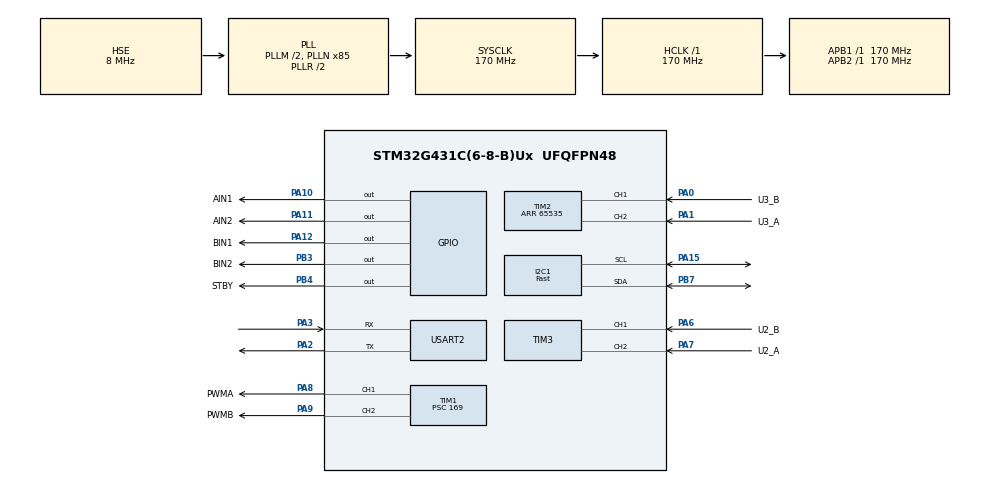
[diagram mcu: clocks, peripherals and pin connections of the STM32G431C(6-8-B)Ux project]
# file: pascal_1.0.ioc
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I2C1.I2C_Speed_Mode=I2C_Fast
I2C1.Timing=0x40621236
Mcu.Family=STM32G4
Mcu.Name=STM32G431C(6-8-B)Ux
Mcu.Package=UFQFPN48
NVIC.I2C1_EV_IRQn=true\:0\:0\:false\:false\:true\:true\:true\:true
NVIC.PriorityGroup=NVIC_PRIORITYGROUP_4
NVIC.TIM2_IRQn=true\:0\:0\:false\:false\:true\:true\:true\:true
NVIC.TIM3_IRQn=true\:0\:0\:false\:false\:true\:true\:true\:true
PA0.GPIO_Label=U3_B
PA0.GPIO_PuPd=GPIO_PULLDOWN
PA0.Signal=S_TIM2_CH1
PA1.GPIO_Label=U3_A
PA1.GPIO_PuPd=GPIO_PULLDOWN
PA1.Signal=S_TIM2_CH2
PA10.GPIO_Label=AIN1
PA10.Signal=GPIO_Output
PA11.GPIO_Label=AIN2
PA11.Signal=GPIO_Output
PA12.GPIO_Label=BIN1
PA12.Signal=GPIO_Output
PA13.Mode=Serial_Wire
PA13.Signal=SYS_JTMS-SWDIO
PA14.Mode=Serial_Wire
PA14.Signal=SYS_JTCK-SWCLK
PA15.Mode=I2C
PA15.Signal=I2C1_SCL
PA2.Mode=Asynchronous
PA2.Signal=USART2_TX
PA3.Mode=Asynchronous
PA3.Signal=USART2_RX
PA6.GPIO_Label=U2_B
PA6.GPIO_PuPd=GPIO_PULLDOWN
PA6.Signal=S_TIM3_CH1
PA7.GPIO_Label=U2_A
PA7.GPIO_PuPd=GPIO_PULLDOWN
PA7.Signal=S_TIM3_CH2
PA8.GPIO_Label=PWMA
PA8.Signal=S_TIM1_CH1
PA9.GPIO_Label=PWMB
PA9.Signal=S_TIM1_CH2
PB3.GPIO_Label=BIN2
PB3.Signal=GPIO_Output
PB4.GPIO_Label=STBY
PB4.Signal=GPIO_Output
PB7.Mode=I2C
PB7.Signal=I2C1_SDA
PF0-OSC_IN.Mode=HSE-External-Oscillator
PF0-OSC_IN.Signal=RCC_OSC_IN
PF1-OSC_OUT.Mode=HSE-External-Oscillator
PF1-OSC_OUT.Signal=RCC_OSC_OUT
ProjectManager.HeapSize=0x200
ProjectManager.StackSize=0x400
ProjectManager.TargetToolchain=STM32CubeIDE
RCC.ADC12Freq_Value=170000000
RCC.AHBFreq_Value=170000000
RCC.APB1Freq_Value=170000000
RCC.APB1TimFreq_Value=170000000
RCC.APB2Freq_Value=170000000
RCC.APB2TimFreq_Value=170000000
RCC.CortexFreq_Value=170000000
RCC.EXTERNAL_CLOCK_VALUE=12288000
RCC.HCLKFreq_Value=170000000
RCC.HSE_VALUE=8000000
RCC.HSI48_VALUE=48000000
RCC.HSI_VALUE=16000000
RCC.LSE_VALUE=32768
RCC.PLLM=RCC_PLLM_DIV2
RCC.PLLN=85
RCC.PLLSourceVirtual=RCC_PLLSOURCE_HSE
RCC.SYSCLKFreq_VALUE=170000000
RCC.SYSCLKSource=RCC_SYSCLKSOURCE_PLLCLK
RCC.USBFreq_Value=170000000
RCC.VCOOutputFreq_Value=340000000
SH.S_TIM1_CH1.0=TIM1_CH1,PWM Generation1 CH1
SH.S_TIM1_CH2.0=TIM1_CH2,PWM Generation2 CH2
SH.S_TIM2_CH1.0=TIM2_CH1,Encoder_Interface
SH.S_TIM2_CH2.0=TIM2_CH2,Encoder_Interface
SH.S_TIM3_CH1.0=TIM3_CH1,Encoder_Interface
SH.S_TIM3_CH2.0=TIM3_CH2,Encoder_Interface
TIM1.Channel-PWM\ Generation1\ CH1=TIM_CHANNEL_1
TIM1.Channel-PWM\ Generation2\ CH2=TIM_CHANNEL_2
TIM1.PeriodNoDither=1000
TIM1.Prescaler=169
TIM2.PeriodNoDither=65535
USART2.VirtualMode-Asynchronous=VM_ASYNC
VP_SYS_VS_DBSignals.Mode=DisableDeadBatterySignals
board=custom

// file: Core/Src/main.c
/* USER CODE BEGIN Header */
/**
  ******************************************************************************
  * @file           : main.c
  * @brief          : Main program body
  ******************************************************************************
  * @attention
  *
  * Copyright (c) 2026 STMicroelectronics.
  * All rights reserved.
  *
  * This software is licensed under terms that can be found in the LICENSE file
  * in the root directory of this software component.
  * If no LICENSE file comes with this software, it is provided AS-IS.
  *
  ******************************************************************************
  */
/* USER CODE END Header */
#include "main.h"

/* USER CODE BEGIN Includes */
#include "motor.h"
#include "encoder.h"
#include <stdio.h>
/* USER CODE END Includes */

I2C_HandleTypeDef hi2c1;

TIM_HandleTypeDef htim1;
TIM_HandleTypeDef htim2;
TIM_HandleTypeDef htim3;

UART_HandleTypeDef huart2;

/* USER CODE BEGIN PV */

//float d = 0;
int16_t speed=950;

/* USER CODE END PV */

void SystemClock_Config(void);
static void MX_GPIO_Init(void);
static void MX_I2C1_Init(void);
static void MX_TIM1_Init(void);
static void MX_TIM2_Init(void);
static void MX_TIM3_Init(void);
static void MX_USART2_UART_Init(void);

/* USER CODE BEGIN 0 */
int __io_putchar(int ch)
{
    HAL_UART_Transmit(&huart2, (uint8_t*)&ch, 1, HAL_MAX_DELAY);
    return ch;
}
/* USER CODE END 0 */

int main(void)
{

  /* MCU Configuration--------------------------------------------------------*/

  /* Reset of all peripherals, Initializes the Flash interface and the Systick. */
  HAL_Init();

  /* Configure the system clock */
  SystemClock_Config();

  /* Initialize all configured peripherals */
  MX_GPIO_Init();
  MX_I2C1_Init();
  MX_TIM1_Init();
  MX_TIM2_Init();
  MX_TIM3_Init();
  MX_USART2_UART_Init();
  /* USER CODE BEGIN 2 */
  Motor_Init();
  Encoder_Init();
  /* USER CODE END 2 */

  /* Infinite loop */
  while (1)
  {

    /* USER CODE BEGIN 3 */

//	  Motor_Forward(speed);

	  Encoder_Update();
//
	  printf("%f %f \r\n",Encoder_GetDistanceLeft(),Encoder_GetDistanceRight());
//
	  HAL_Delay(50);

	  //HAL_Delay(200);
  }
  /* USER CODE END 3 */
}

void SystemClock_Config(void)
{
  RCC_OscInitTypeDef RCC_OscInitStruct = {0};
  RCC_ClkInitTypeDef RCC_ClkInitStruct = {0};

  /** Configure the main internal regulator output voltage
  */
  HAL_PWREx_ControlVoltageScaling(PWR_REGULATOR_VOLTAGE_SCALE1_BOOST);

  /** Initializes the RCC Oscillators according to the specified parameters
  * in the RCC_OscInitTypeDef structure.
  */
  RCC_OscInitStruct.OscillatorType = RCC_OSCILLATORTYPE_HSE;
  RCC_OscInitStruct.HSEState = RCC_HSE_ON;
  RCC_OscInitStruct.PLL.PLLState = RCC_PLL_ON;
  RCC_OscInitStruct.PLL.PLLSource = RCC_PLLSOURCE_HSE;
  RCC_OscInitStruct.PLL.PLLM = RCC_PLLM_DIV2;
  RCC_OscInitStruct.PLL.PLLN = 85;
  RCC_OscInitStruct.PLL.PLLP = RCC_PLLP_DIV2;
  RCC_OscInitStruct.PLL.PLLQ = RCC_PLLQ_DIV2;
  RCC_OscInitStruct.PLL.PLLR = RCC_PLLR_DIV2;
  if (HAL_RCC_OscConfig(&RCC_OscInitStruct) != HAL_OK)
  {
    Error_Handler();
  }

  /** Initializes the CPU, AHB and APB buses clocks
  */
  RCC_ClkInitStruct.ClockType = RCC_CLOCKTYPE_HCLK|RCC_CLOCKTYPE_SYSCLK
                              |RCC_CLOCKTYPE_PCLK1|RCC_CLOCKTYPE_PCLK2;
  RCC_ClkInitStruct.SYSCLKSource = RCC_SYSCLKSOURCE_PLLCLK;
  RCC_ClkInitStruct.AHBCLKDivider = RCC_SYSCLK_DIV1;
  RCC_ClkInitStruct.APB1CLKDivider = RCC_HCLK_DIV1;
  RCC_ClkInitStruct.APB2CLKDivider = RCC_HCLK_DIV1;

  if (HAL_RCC_ClockConfig(&RCC_ClkInitStruct, FLASH_LATENCY_4) != HAL_OK)
  {
    Error_Handler();
  }
}

static void MX_I2C1_Init(void)
{

  hi2c1.Instance = I2C1;
  hi2c1.Init.Timing = 0x40621236;
  hi2c1.Init.OwnAddress1 = 0;
  hi2c1.Init.AddressingMode = I2C_ADDRESSINGMODE_7BIT;
  hi2c1.Init.DualAddressMode = I2C_DUALADDRESS_DISABLE;
  hi2c1.Init.OwnAddress2 = 0;
  hi2c1.Init.OwnAddress2Masks = I2C_OA2_NOMASK;
  hi2c1.Init.GeneralCallMode = I2C_GENERALCALL_DISABLE;
  hi2c1.Init.NoStretchMode = I2C_NOSTRETCH_DISABLE;
  if (HAL_I2C_Init(&hi2c1) != HAL_OK)
  {
    Error_Handler();
  }

  /** Configure Analogue filter
  */
  if (HAL_I2CEx_ConfigAnalogFilter(&hi2c1, I2C_ANALOGFILTER_ENABLE) != HAL_OK)
  {
    Error_Handler();
  }

  /** Configure Digital filter
  */
  if (HAL_I2CEx_ConfigDigitalFilter(&hi2c1, 0) != HAL_OK)
  {
    Error_Handler();
  }

}

static void MX_TIM1_Init(void)
{

  TIM_MasterConfigTypeDef sMasterConfig = {0};
  TIM_OC_InitTypeDef sConfigOC = {0};
  TIM_BreakDeadTimeConfigTypeDef sBreakDeadTimeConfig = {0};

  htim1.Instance = TIM1;
  htim1.Init.Prescaler = 169;
  htim1.Init.CounterMode = TIM_COUNTERMODE_UP;
  htim1.Init.Period = 1000;
  htim1.Init.ClockDivision = TIM_CLOCKDIVISION_DIV1;
  htim1.Init.RepetitionCounter = 0;
  htim1.Init.AutoReloadPreload = TIM_AUTORELOAD_PRELOAD_DISABLE;
  if (HAL_TIM_PWM_Init(&htim1) != HAL_OK)
  {
    Error_Handler();
  }
  sMasterConfig.MasterOutputTrigger = TIM_TRGO_RESET;
  sMasterConfig.MasterOutputTrigger2 = TIM_TRGO2_RESET;
  sMasterConfig.MasterSlaveMode = TIM_MASTERSLAVEMODE_DISABLE;
  if (HAL_TIMEx_MasterConfigSynchronization(&htim1, &sMasterConfig) != HAL_OK)
  {
    Error_Handler();
  }
  sConfigOC.OCMode = TIM_OCMODE_PWM1;
  sConfigOC.Pulse = 0;
  sConfigOC.OCPolarity = TIM_OCPOLARITY_HIGH;
  sConfigOC.OCNPolarity = TIM_OCNPOLARITY_HIGH;
  sConfigOC.OCFastMode = TIM_OCFAST_DISABLE;
  sConfigOC.OCIdleState = TIM_OCIDLESTATE_RESET;
  sConfigOC.OCNIdleState = TIM_OCNIDLESTATE_RESET;
  if (HAL_TIM_PWM_ConfigChannel(&htim1, &sConfigOC, TIM_CHANNEL_1) != HAL_OK)
  {
    Error_Handler();
  }
  if (HAL_TIM_PWM_ConfigChannel(&htim1, &sConfigOC, TIM_CHANNEL_2) != HAL_OK)
  {
    Error_Handler();
  }
  sBreakDeadTimeConfig.OffStateRunMode = TIM_OSSR_DISABLE;
  sBreakDeadTimeConfig.OffStateIDLEMode = TIM_OSSI_DISABLE;
  sBreakDeadTimeConfig.LockLevel = TIM_LOCKLEVEL_OFF;
  sBreakDeadTimeConfig.DeadTime = 0;
  sBreakDeadTimeConfig.BreakState = TIM_BREAK_DISABLE;
  sBreakDeadTimeConfig.BreakPolarity = TIM_BREAKPOLARITY_HIGH;
  sBreakDeadTimeConfig.BreakFilter = 0;
  sBreakDeadTimeConfig.BreakAFMode = TIM_BREAK_AFMODE_INPUT;
  sBreakDeadTimeConfig.Break2State = TIM_BREAK2_DISABLE;
  sBreakDeadTimeConfig.Break2Polarity = TIM_BREAK2POLARITY_HIGH;
  sBreakDeadTimeConfig.Break2Filter = 0;
  sBreakDeadTimeConfig.Break2AFMode = TIM_BREAK_AFMODE_INPUT;
  sBreakDeadTimeConfig.AutomaticOutput = TIM_AUTOMATICOUTPUT_DISABLE;
  if (HAL_TIMEx_ConfigBreakDeadTime(&htim1, &sBreakDeadTimeConfig) != HAL_OK)
  {
    Error_Handler();
  }
  HAL_TIM_MspPostInit(&htim1);

}

static void MX_TIM2_Init(void)
{

  TIM_Encoder_InitTypeDef sConfig = {0};
  TIM_MasterConfigTypeDef sMasterConfig = {0};

  htim2.Instance = TIM2;
  htim2.Init.Prescaler = 0;
  htim2.Init.CounterMode = TIM_COUNTERMODE_UP;
  htim2.Init.Period = 65535;
  htim2.Init.ClockDivision = TIM_CLOCKDIVISION_DIV1;
  htim2.Init.AutoReloadPreload = TIM_AUTORELOAD_PRELOAD_DISABLE;
  sConfig.EncoderMode = TIM_ENCODERMODE_TI1;
  sConfig.IC1Polarity = TIM_ICPOLARITY_RISING;
  sConfig.IC1Selection = TIM_ICSELECTION_DIRECTTI;
  sConfig.IC1Prescaler = TIM_ICPSC_DIV1;
  sConfig.IC1Filter = 0;
  sConfig.IC2Polarity = TIM_ICPOLARITY_RISING;
  sConfig.IC2Selection = TIM_ICSELECTION_DIRECTTI;
  sConfig.IC2Prescaler = TIM_ICPSC_DIV1;
  sConfig.IC2Filter = 0;
  if (HAL_TIM_Encoder_Init(&htim2, &sConfig) != HAL_OK)
  {
    Error_Handler();
  }
  sMasterConfig.MasterOutputTrigger = TIM_TRGO_RESET;
  sMasterConfig.MasterSlaveMode = TIM_MASTERSLAVEMODE_DISABLE;
  if (HAL_TIMEx_MasterConfigSynchronization(&htim2, &sMasterConfig) != HAL_OK)
  {
    Error_Handler();
  }

}

static void MX_TIM3_Init(void)
{

  TIM_Encoder_InitTypeDef sConfig = {0};
  TIM_MasterConfigTypeDef sMasterConfig = {0};

  htim3.Instance = TIM3;
  htim3.Init.Prescaler = 0;
  htim3.Init.CounterMode = TIM_COUNTERMODE_UP;
  htim3.Init.Period = 65535;
  htim3.Init.ClockDivision = TIM_CLOCKDIVISION_DIV1;
  htim3.Init.AutoReloadPreload = TIM_AUTORELOAD_PRELOAD_DISABLE;
  sConfig.EncoderMode = TIM_ENCODERMODE_TI1;
  sConfig.IC1Polarity = TIM_ICPOLARITY_RISING;
  sConfig.IC1Selection = TIM_ICSELECTION_DIRECTTI;
  sConfig.IC1Prescaler = TIM_ICPSC_DIV1;
  sConfig.IC1Filter = 0;
  sConfig.IC2Polarity = TIM_ICPOLARITY_RISING;
  sConfig.IC2Selection = TIM_ICSELECTION_DIRECTTI;
  sConfig.IC2Prescaler = TIM_ICPSC_DIV1;
  sConfig.IC2Filter = 0;
  if (HAL_TIM_Encoder_Init(&htim3, &sConfig) != HAL_OK)
  {
    Error_Handler();
  }
  sMasterConfig.MasterOutputTrigger = TIM_TRGO_RESET;
  sMasterConfig.MasterSlaveMode = TIM_MASTERSLAVEMODE_DISABLE;
  if (HAL_TIMEx_MasterConfigSynchronization(&htim3, &sMasterConfig) != HAL_OK)
  {
    Error_Handler();
  }

}

static void MX_USART2_UART_Init(void)
{

  huart2.Instance = USART2;
  huart2.Init.BaudRate = 115200;
  huart2.Init.WordLength = UART_WORDLENGTH_8B;
  huart2.Init.StopBits = UART_STOPBITS_1;
  huart2.Init.Parity = UART_PARITY_NONE;
  huart2.Init.Mode = UART_MODE_TX_RX;
  huart2.Init.HwFlowCtl = UART_HWCONTROL_NONE;
  huart2.Init.OverSampling = UART_OVERSAMPLING_16;
  huart2.Init.OneBitSampling = UART_ONE_BIT_SAMPLE_DISABLE;
  huart2.Init.ClockPrescaler = UART_PRESCALER_DIV1;
  huart2.AdvancedInit.AdvFeatureInit = UART_ADVFEATURE_NO_INIT;
  if (HAL_UART_Init(&huart2) != HAL_OK)
  {
    Error_Handler();
  }
  if (HAL_UARTEx_SetTxFifoThreshold(&huart2, UART_TXFIFO_THRESHOLD_1_8) != HAL_OK)
  {
    Error_Handler();
  }
  if (HAL_UARTEx_SetRxFifoThreshold(&huart2, UART_RXFIFO_THRESHOLD_1_8) != HAL_OK)
  {
    Error_Handler();
  }
  if (HAL_UARTEx_DisableFifoMode(&huart2) != HAL_OK)
  {
    Error_Handler();
  }

}

static void MX_GPIO_Init(void)
{
  GPIO_InitTypeDef GPIO_InitStruct = {0};

  /* GPIO Ports Clock Enable */
  __HAL_RCC_GPIOF_CLK_ENABLE();
  __HAL_RCC_GPIOA_CLK_ENABLE();
  __HAL_RCC_GPIOB_CLK_ENABLE();

  /*Configure GPIO pin Output Level */
  HAL_GPIO_WritePin(GPIOA, AIN1_Pin|AIN2_Pin|BIN1_Pin, GPIO_PIN_RESET);

  /*Configure GPIO pin Output Level */
  HAL_GPIO_WritePin(GPIOB, BIN2_Pin|STBY_Pin, GPIO_PIN_RESET);

  /*Configure GPIO pins : AIN1_Pin AIN2_Pin BIN1_Pin */
  GPIO_InitStruct.Pin = AIN1_Pin|AIN2_Pin|BIN1_Pin;
  GPIO_InitStruct.Mode = GPIO_MODE_OUTPUT_PP;
  GPIO_InitStruct.Pull = GPIO_NOPULL;
  GPIO_InitStruct.Speed = GPIO_SPEED_FREQ_LOW;
  HAL_GPIO_Init(GPIOA, &GPIO_InitStruct);

  /*Configure GPIO pins : BIN2_Pin STBY_Pin */
  GPIO_InitStruct.Pin = BIN2_Pin|STBY_Pin;
  GPIO_InitStruct.Mode = GPIO_MODE_OUTPUT_PP;
  GPIO_InitStruct.Pull = GPIO_NOPULL;
  GPIO_InitStruct.Speed = GPIO_SPEED_FREQ_LOW;
  HAL_GPIO_Init(GPIOB, &GPIO_InitStruct);

}

void Error_Handler(void)
{
  __disable_irq();
  while (1)
  {
  }
}
